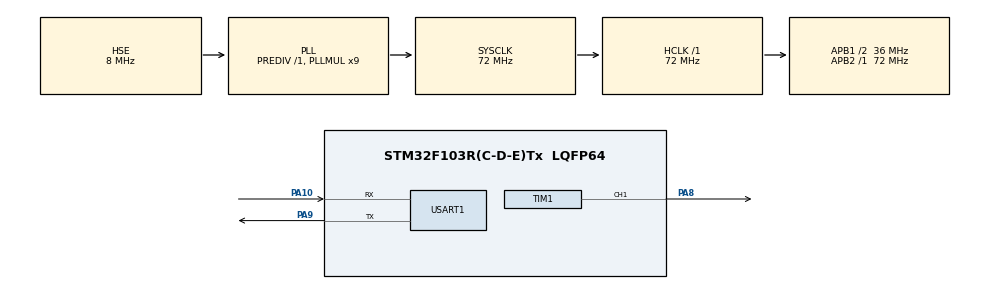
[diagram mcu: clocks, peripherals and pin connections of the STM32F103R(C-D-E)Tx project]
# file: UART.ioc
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Dma.Request0=USART1_RX
Dma.Request1=USART1_TX
Dma.USART1_RX.0.Direction=DMA_PERIPH_TO_MEMORY
Dma.USART1_RX.0.Instance=DMA1_Channel5
Dma.USART1_RX.0.MemDataAlignment=DMA_MDATAALIGN_BYTE
Dma.USART1_RX.0.MemInc=DMA_MINC_ENABLE
Dma.USART1_RX.0.Mode=DMA_NORMAL
Dma.USART1_RX.0.PeriphDataAlignment=DMA_PDATAALIGN_BYTE
Dma.USART1_RX.0.PeriphInc=DMA_PINC_DISABLE
Dma.USART1_RX.0.Priority=DMA_PRIORITY_LOW
Dma.USART1_TX.1.Direction=DMA_MEMORY_TO_PERIPH
Dma.USART1_TX.1.Instance=DMA1_Channel4
Dma.USART1_TX.1.MemDataAlignment=DMA_MDATAALIGN_BYTE
Dma.USART1_TX.1.MemInc=DMA_MINC_ENABLE
Dma.USART1_TX.1.Mode=DMA_NORMAL
Dma.USART1_TX.1.PeriphDataAlignment=DMA_PDATAALIGN_BYTE
Dma.USART1_TX.1.PeriphInc=DMA_PINC_DISABLE
Dma.USART1_TX.1.Priority=DMA_PRIORITY_LOW
Mcu.Family=STM32F1
Mcu.Name=STM32F103R(C-D-E)Tx
Mcu.Package=LQFP64
NVIC.DMA1_Channel4_IRQn=true\:0\:0\:false\:false\:true\:false\:true\:true
NVIC.DMA1_Channel5_IRQn=true\:0\:0\:false\:false\:true\:false\:true\:true
NVIC.PriorityGroup=NVIC_PRIORITYGROUP_4
NVIC.USART1_IRQn=true\:0\:0\:false\:false\:true\:true\:true\:true
PA10.Mode=Asynchronous
PA10.Signal=USART1_RX
PA13.Mode=Serial_Wire
PA13.Signal=SYS_JTMS-SWDIO
PA14.Mode=Serial_Wire
PA14.Signal=SYS_JTCK-SWCLK
PA8.Signal=S_TIM1_CH1
PA9.Mode=Asynchronous
PA9.Signal=USART1_TX
PD0-OSC_IN.Mode=HSE-External-Oscillator
PD0-OSC_IN.Signal=RCC_OSC_IN
PD1-OSC_OUT.Mode=HSE-External-Oscillator
PD1-OSC_OUT.Signal=RCC_OSC_OUT
ProjectManager.HeapSize=0x200
ProjectManager.StackSize=0x400
ProjectManager.TargetToolchain=MDK-ARM V5.32
RCC.AHBFreq_Value=72000000
RCC.APB1CLKDivider=RCC_HCLK_DIV2
RCC.APB1Freq_Value=36000000
RCC.APB1TimFreq_Value=72000000
RCC.APB2Freq_Value=72000000
RCC.APB2TimFreq_Value=72000000
RCC.HCLKFreq_Value=72000000
RCC.PLLMUL=RCC_PLL_MUL9
RCC.PLLSourceVirtual=RCC_PLLSOURCE_HSE
RCC.SYSCLKFreq_VALUE=72000000
RCC.SYSCLKSource=RCC_SYSCLKSOURCE_PLLCLK
RCC.USBFreq_Value=72000000
SH.S_TIM1_CH1.0=TIM1_CH1,PWM Generation1 CH1
TIM1.Channel-PWM\ Generation1\ CH1=TIM_CHANNEL_1
TIM1.Period=1000-1
TIM1.Prescaler=36-1
USART1.VirtualMode=VM_ASYNC
VP_TIM1_VS_ClockSourceINT.Mode=Internal
board=custom

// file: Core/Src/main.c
/* USER CODE BEGIN Header */
/**
  ******************************************************************************
  * @file           : main.c
  * @brief          : Main program body
  ******************************************************************************
  * @attention
  *
  * Copyright (c) 2024 STMicroelectronics.
  * All rights reserved.
  *
  * This software is licensed under terms that can be found in the LICENSE file
  * in the root directory of this software component.
  * If no LICENSE file comes with this software, it is provided AS-IS.
  *
  ******************************************************************************
  */
/* USER CODE END Header */
#include "main.h"
#include "dma.h"
#include "tim.h"
#include "usart.h"
#include "gpio.h"

void SystemClock_Config(void);

/* USER CODE BEGIN 0 */
uint8_t buf[100];
void HAL_UARTEx_RxEventCallback(UART_HandleTypeDef *huart, uint16_t Size)
{
  if (huart == &huart1)
  {
    if (strcmp(buf, "on") == 0)
    {
      //HAL_UART_Transmit(&huart1, "on\r\n", sizeof("on\r\n"), 100);
      __HAL_TIM_SetCompare(&htim1, TIM_CHANNEL_1, 0);
    }
    if (strcmp(buf, "off") == 0)
    {
      //HAL_UART_Transmit(&huart1, "off\r\n", sizeof("off\r\n"), 100);
      __HAL_TIM_SetCompare(&htim1, TIM_CHANNEL_1, 999);
    }
    if (strcmp(buf, "huxi") == 0)
    {
      for (int i = 0; i < 1000; i++)
      {
        __HAL_TIM_SetCompare(&htim1, TIM_CHANNEL_1, i);
        int t = 31270;
        while (t--);
      }
      for (int i = 0; i < 1000; i++)
      {
        __HAL_TIM_SetCompare(&htim1, TIM_CHANNEL_1, 999 - i);
        int t = 31270;
        while (t--);//same as HAL_DELAY
      }
    }
    memset(buf, 0, sizeof(buf));//clear buf
    //HAL_UART_Transmit(&huart1, "successfully receive\r\n", sizeof("successfully receive\r\n"), 100);
    HAL_UARTEx_ReceiveToIdle_DMA(&huart1, buf, 100);

  }
}
/* USER CODE END 0 */

int main(void)
{

  /* MCU Configuration--------------------------------------------------------*/

  /* Reset of all peripherals, Initializes the Flash interface and the Systick. */
  HAL_Init();

  /* Configure the system clock */
  SystemClock_Config();

  /* Initialize all configured peripherals */
  MX_GPIO_Init();
  MX_DMA_Init();
  MX_USART1_UART_Init();
  MX_TIM1_Init();
  /* USER CODE BEGIN 2 */
  //char str[] = "HELLO\r\n";
  //equals to  uint8_t
  //HAL_UART_Transmit(&huart1, str, sizeof(str), 100);
  //HAL_UART_Transmit_IT(&huart1, str, sizeof(str));
  //huan cun qu buf
  HAL_TIM_PWM_Start(&htim1, TIM_CHANNEL_1);
  HAL_UART_Transmit(&huart1, "Hello 23121179 王宇轩\r\n", sizeof("Hello 23121179 王宇轩\r\n"), 100);
  //HAL_UARTEx_ReceiveToIdle_DMA(&huart1, buf, 100);

  /* USER CODE END 2 */

  /* Infinite loop */
  /* USER CODE BEGIN WHILE */
  while (1)
  {
    //memset(buf, 0, 100);
    HAL_UARTEx_ReceiveToIdle_DMA(&huart1, buf, 100);

    HAL_Delay(1000);

    /* USER CODE END WHILE */

  }
}

void SystemClock_Config(void)
{
  RCC_OscInitTypeDef RCC_OscInitStruct = {0};
  RCC_ClkInitTypeDef RCC_ClkInitStruct = {0};

  /** Initializes the RCC Oscillators according to the specified parameters
  * in the RCC_OscInitTypeDef structure.
  */
  RCC_OscInitStruct.OscillatorType = RCC_OSCILLATORTYPE_HSE;
  RCC_OscInitStruct.HSEState = RCC_HSE_ON;
  RCC_OscInitStruct.HSEPredivValue = RCC_HSE_PREDIV_DIV1;
  RCC_OscInitStruct.HSIState = RCC_HSI_ON;
  RCC_OscInitStruct.PLL.PLLState = RCC_PLL_ON;
  RCC_OscInitStruct.PLL.PLLSource = RCC_PLLSOURCE_HSE;
  RCC_OscInitStruct.PLL.PLLMUL = RCC_PLL_MUL9;
  if (HAL_RCC_OscConfig(&RCC_OscInitStruct) != HAL_OK)
  {
    Error_Handler();
  }

  /** Initializes the CPU, AHB and APB buses clocks
  */
  RCC_ClkInitStruct.ClockType = RCC_CLOCKTYPE_HCLK|RCC_CLOCKTYPE_SYSCLK
                              |RCC_CLOCKTYPE_PCLK1|RCC_CLOCKTYPE_PCLK2;
  RCC_ClkInitStruct.SYSCLKSource = RCC_SYSCLKSOURCE_PLLCLK;
  RCC_ClkInitStruct.AHBCLKDivider = RCC_SYSCLK_DIV1;
  RCC_ClkInitStruct.APB1CLKDivider = RCC_HCLK_DIV2;
  RCC_ClkInitStruct.APB2CLKDivider = RCC_HCLK_DIV1;

  if (HAL_RCC_ClockConfig(&RCC_ClkInitStruct, FLASH_LATENCY_2) != HAL_OK)
  {
    Error_Handler();
  }
}

void Error_Handler(void)
{
  __disable_irq();
  while (1)
  {
  }
}
